# RX64M_PTPEDMAC_Pilot register map
File version: 1.0
RX64M_PTPEDMAC_Pilot peripheral registers generated from iodefine.h (pilot).
Registers are 32-bit, read-write, reset 0x0 unless marked. A register's access mark holds for its fields unless they carry their own. Offsets are from the block's base; lines under a group give offsets from that group; [hi:lo] are bit positions; {n}, {i} and the like mark numbered series; 'fields as' and 'values as' point back to an identical list; <NAME> marks a mode.

## Memory map
0x000C0400 PTPEDMAC size 0xDC

## PTPEDMAC
Base 0x000C0400
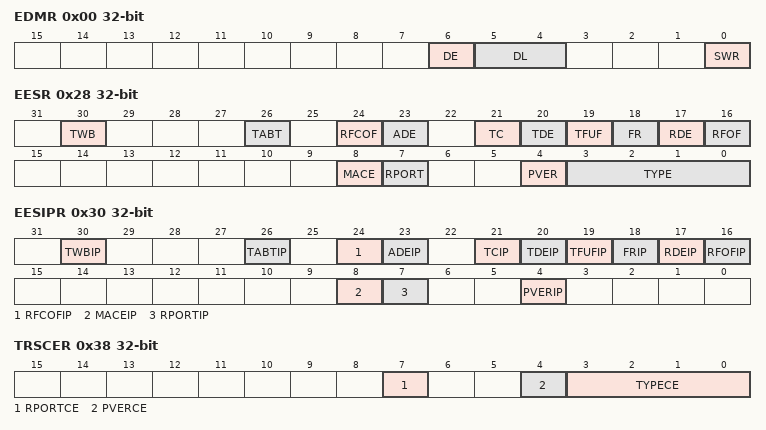
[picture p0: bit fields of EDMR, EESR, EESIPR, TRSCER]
0x00 EDMR
  [6] DE, [5:4] DL, [0] SWR
0x08 EDTRR
  [0] TR
0x10 EDRRR
  [0] RR
0x18 TDLAR
0x20 RDLAR
0x28 EESR
  [30] TWB, [26] TABT, [24] RFCOF, [23] ADE, [21] TC, [20] TDE, [19] TFUF, [18] FR, [17] RDE, [16] RFOF, [8] MACE, [7] RPORT, [4] PVER, [3:0] TYPE
0x30 EESIPR
  [30] TWBIP, [26] TABTIP, [24] RFCOFIP, [23] ADEIP, [21] TCIP, [20] TDEIP, [19] TFUFIP, [18] FRIP, [17] RDEIP, [16] RFOFIP, [8] MACEIP, [7] RPORTIP, [4] PVERIP
0x38 TRSCER access not given reset not defined
  [7] RPORTCE, [4] PVERCE, [3:0] TYPECE
0x40 RMFCR
  [15:0] MFC
0x48 TFTR
  [10:0] TFT
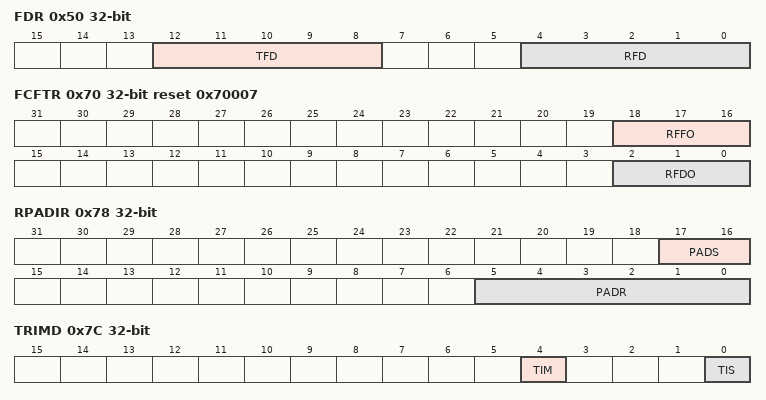
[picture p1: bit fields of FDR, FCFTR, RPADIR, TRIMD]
0x50 FDR
  [12:8] TFD, [4:0] RFD
0x58 RMCR
  [0] RNR
0x64 TFUCR
  [15:0] UNDER
0x68 RFOCR
  [15:0] OVER
0x6C IOSR access not given reset not defined
  [0] ELB
0x70 FCFTR reset 0x70007
  [18:16] RFFO, [2:0] RFDO
0x78 RPADIR
  [17:16] PADS, [5:0] PADR
0x7C TRIMD
  [4] TIM, [0] TIS
0xC8 RBWAR ro
0xCC RDFAR ro
0xD4 TBRAR ro
0xD8 TDFAR ro
